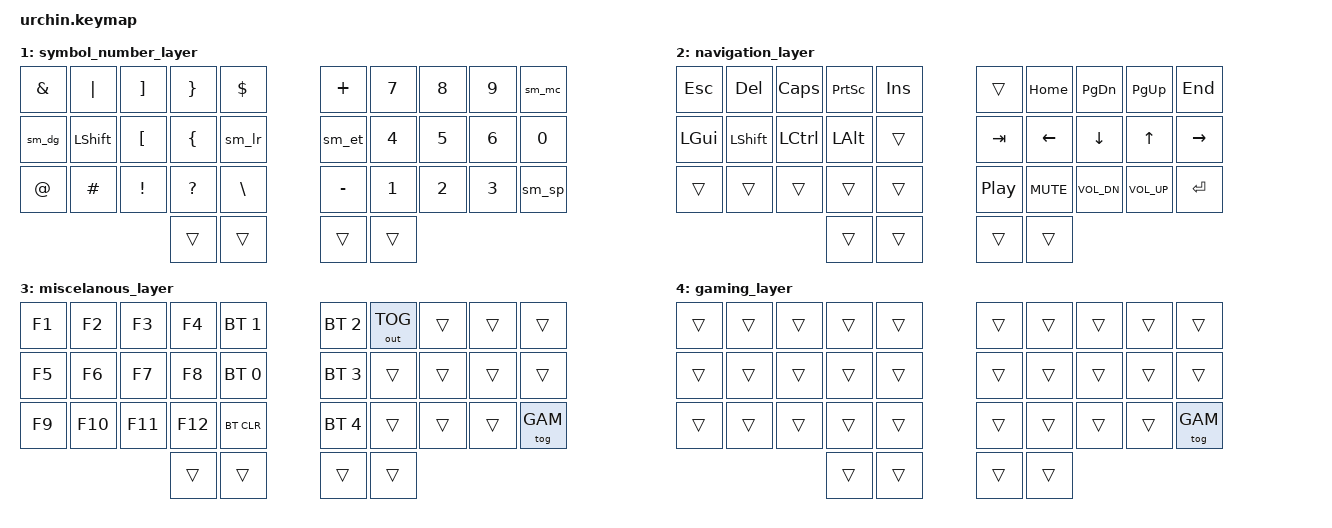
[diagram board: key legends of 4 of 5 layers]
// Copyright (c) 2022 The ZMK Contributors
// SPDX-License-Identifier: MIT

#include <behaviors.dtsi>
#include <dt-bindings/zmk/keys.h>
#include <dt-bindings/zmk/bt.h>
#include <dt-bindings/zmk/outputs.h>

// Home row mods macro
#define HRML(k1,k2,k3,k4) &ht LGUI k1 &ht LSHFT k2 &ht LCTRL k3  &ht LALT  k4
#define HRMR(k1,k2,k3) &ht RALT k1 &ht RCTRL k2 &ht RSHFT k3

#define WIN 0
#define SYM 1
#define NAV 2
#define MSC 3
#define GAM 4

/ {
    behaviors {
        ht: hold_tap {
            compatible = "zmk,behavior-hold-tap";
            #binding-cells = <2>;
            flavor = "tap-preferred";
            tapping-term-ms = <220>;
            quick-tap-ms = <150>;
            bindings = <&kp>, <&kp>;
        };
        sm_pu: left_parenthesis_underscore {
            compatible = "zmk,behavior-mod-morph";
            #binding-cells = <0>;
            bindings = <&kp LPAR>, <&kp UNDER>;
            mods = <(MOD_LSFT|MOD_RSFT)>;
        };
        sm_ca: comma_apostrophe {
            compatible = "zmk,behavior-mod-morph";
            #binding-cells = <0>;
            bindings = <&kp COMMA>, <&kp APOS>;
            mods = <(MOD_LSFT|MOD_RSFT)>;
        };
        sm_dq: dot_doublequote {
            compatible = "zmk,behavior-mod-morph";
            #binding-cells = <0>;
            bindings = <&kp DOT>, <&kp DQT>;
            mods = <(MOD_LSFT|MOD_RSFT)>;
        };
        sm_rs: return_slash {
            compatible = "zmk,behavior-mod-morph";
            #binding-cells = <0>;
            bindings = <&kp RET>, <&kp KP_SLASH>;
            mods = <(MOD_LSFT|MOD_RSFT)>;
        };

        sm_mc: multiply_exponent {
            compatible = "zmk,behavior-mod-morph";
            #binding-cells = <0>;
            bindings = <&kp KP_MULTIPLY>, <&kp CARET>;
            mods = <(MOD_LSFT|MOD_RSFT)>;
        };
        sm_dg: double_quote_grave {
            compatible = "zmk,behavior-mod-morph";
            #binding-cells = <0>;
            bindings = <&kp DQT>, <&kp GRAVE>;
            mods = <(MOD_LSFT|MOD_RSFT)>;
        };
        sm_lr: left_right_arrow {
            compatible = "zmk,behavior-mod-morph";
            #binding-cells = <0>;
            bindings = <&kp LT>, <&kp GT>;
            mods = <(MOD_LSFT|MOD_RSFT)>;
        };
        sm_et: equal_tilde {
            compatible = "zmk,behavior-mod-morph";
            #binding-cells = <0>;
            bindings = <&kp EQUAL>, <&kp TILDE>;
            mods = <(MOD_LSFT|MOD_RSFT)>;
        };
        sm_sp: slash_percent {
            compatible = "zmk,behavior-mod-morph";
            #binding-cells = <0>;
            bindings = <&kp KP_SLASH>, <&kp PRCNT>;
            mods = <(MOD_LSFT|MOD_RSFT)>;
        };
    };

    conditional_layers {
        compatible = "zmk,conditional-layers";
        tri_layer {
            if-layers = <SYM NAV>;
            then-layer = <MSC>;
        };
    };

    keymap {
        compatible = "zmk,keymap";

        default_layer {
            bindings = <
            // Main:                            &ht RCTRL k4
            // ╭───────────┬───────────┬───────────┬───────────┬───────────╮   ╭───────────┬───────────┬───────────┬───────────┬───────────╮
            // │     Q     │     W     │     E     │     R     │     T     │   │     Y     │     U     │     I     │     O     │     P     │
              &kp    Q    &kp    W    &kp    E    &kp    R    &kp    T        &kp    Y    &kp    U    &kp    I    &kp    O    &kp    P
            // ├───────────┼───────────┼───────────┼───────────┼───────────┤   ├───────────┼───────────┼───────────┼───────────┼───────────┤
            // │     A     │     S     │     D     │     F     │     G     │   │     H     │     J     │     K     │     L     │    ( _    │
            HRML(    A     ,     S     ,     D     ,     F )  &kp    G        &kp    H   HRMR(   J     ,     K     ,     L     )   &sm_pu
            // ├───────────┼───────────┼───────────┼───────────┼───────────┤   ├───────────┼───────────┼───────────┼───────────┼───────────┤
            // │     Z     │     X     │     C     │     V     │     B     │   │     N     │     M     │     ,'    │    . "    │    ; :    │
              &kp    Z    &kp    X    &kp    C    &kp    V    &kp    B        &kp    N    &kp    M         &sm_ca      &sm_dq &kp  SEMI
            // ╰───────────┴───────────┴───────────┼───────────┼───────────┤   ├───────────┼───────────┼───────────┴───────────┴───────────╯
            //                                     │    <XX    │   NAV ->  │   │  SYM  </  │    ._.    │
                                                  &kp   BSPC  &lt NAV TAB     &lt SYM RET &kp  SPACE  
            //                                     ╰───────────┴───────────╯   ╰───────────┴───────────╯
            >;
        };

        symbol_number_layer {
            bindings = <
            // Symbols and Numbers:
            // ╭───────────┬───────────┬───────────┬───────────┬───────────╮   ╭───────────┬───────────┬───────────┬───────────┬───────────╮
            // │     &     │     |     │     ]     │     }     │     $     │   │     +     │    7 &    │    8 *    │    9 (    │    * ^    │
              &kp  AMPS   &kp  PIPE   &kp  RBKT   &kp   RBRC  &kp  DOLLAR     &kp  PLUS   &kp    N7   &kp    N8   &kp    N9        &sm_mc
            // ├───────────┼───────────┼───────────┼───────────┼───────────┤   ├───────────┼───────────┼───────────┼───────────┼───────────┤
            // │    " `    │    /^\    │     [     │     {     │    < >    │   │    = ~    │    4 $    │    5 %    │    6 ^    │    0 )    │
                  &sm_dg  &kp  LSHFT  &kp  LBKT   &kp   LBRC       &sm_lr          &sm_et &kp    N4   &kp    N5   &kp    N6   &kp   N0
            // ├───────────┼───────────┼───────────┼───────────┼───────────┤   ├───────────┼───────────┼───────────┼───────────┼───────────┤
            // │     @     │     #     │     !     │     ?     │    \ |    │   │    - _    │    1 !    │    2 @    │    3 #    │    / %    │
              &kp    AT   &kp   HASH  &kp   EXCL  &kp  QMARK  &kp   BSLH      &kp  MINUS  &kp    N1   &kp    N2   &kp    N3       &sm_sp
            // ╰───────────┴───────────┴───────────┼───────────┼───────────┤   ├───────────┼───────────┼───────────┴───────────┴───────────╯
            //                                     │    <XX    │   MISC    │   │     V     │    ._.    │
                                                       &trans      &trans          &trans      &trans
            //                                     ╰───────────┴───────────╯   ╰───────────┴───────────╯
            >;
        };

        navigation_layer {
            bindings = <
            // Navigation:  
            // ╭───────────┬───────────┬───────────┬───────────┬───────────╮   ╭───────────┬───────────┬───────────┬───────────┬───────────╮
            // │    ESC    │    XX>    │ Caps Lock │ Print Scr │  Insert   │   │           │   HOME    │  PG DOWN  │   PG UP   │   END     │
              &kp   ESC   &kp   DEL   &kp   CAPS  &kp  PSCRN  &kp INSERT          &trans  &kp  HOME   &kp  PG_DN  &kp  PG_UP  &kp  END
            // ├───────────┼───────────┼───────────┼───────────┼───────────┤   ├───────────┼───────────┼───────────┼───────────┼───────────┤
            // │    GUI    │   SHIFT   │    CTRL   │    ALT    │           │   │     TAB   │     <     │     V     │    /^\    │     >     │
              &kp  LGUI  &kp  LSHIFT &kp   LCTRL  &kp   LALT      &trans      &kp    TAB  &kp   LEFT  &kp   DOWN  &kp    UP   &kp   RIGHT
            // ├───────────┼───────────┼───────────┼───────────┼───────────┤   ├───────────┼───────────┼───────────┼───────────┼───────────┤
            // │           │           │           │           │           │   │ PLY PAUSE │   MUTE    │ VOL DOWN  │  VOL UP   │    </     │
                  &trans      &trans      &trans      &trans      &trans      &kp  C_PP   &kp C_MUTE  &kp C_VOL_DN &kp C_VOL_UP &kp RET
            // ╰───────────┴───────────┴───────────┼───────────┼───────────┤   ├───────────┼───────────┼───────────┴───────────┴───────────╯
            //                                     │    <XX    │     V     │   │    MISC   │    ._.    │
                                                      &trans      &trans           &trans     &trans
            //                                     ╰───────────┴───────────╯   ╰───────────┴───────────╯
            >;
        };

        miscelanous_layer {
            bindings = <
            // Miscelanous:
            // ╭───────────┬───────────┬───────────┬───────────┬───────────╮   ╭───────────┬───────────┬───────────┬───────────┬───────────╮
            // │    Fn 1   │    Fn 2   │    Fn 3   │    Fn 4   │ PROFILE 1 │   │ PROFILE 2 │ TOGGLEOUT │           │           │           │
              &kp   F1    &kp   F2    &kp   F3    &kp    F4   &bt BT_SEL 1    &bt BT_SEL 2 &out OUT_TOG   &trans      &trans      &trans
            // ├───────────┼───────────┼───────────┼───────────┼───────────┤   ├───────────┼───────────┼───────────┼───────────┼───────────┤
            // │    Fn 5   │    Fn 6   │    Fn 7   │    Fn 8   │ PROFILE 0 │   │ PROFILE 3 │           │           │           │           │
              &kp   F5    &kp   F6    &kp   F7    &kp    F8   &bt BT_SEL 0    &bt BT_SEL 3    &trans      &trans      &trans      &trans
            // ├───────────┼───────────┼───────────┼───────────┼───────────┤   ├───────────┼───────────┼───────────┼───────────┼───────────┤
            // │    Fn 9   │    Fn 10  │    Fn 11  │    Fn 12  │  CLEAR BT │   │ PROFILE 4 │           │           │           │  Gaming   │
              &kp   F9    &kp   F10   &kp   F11   &kp    F12  &bt BT_CLR      &bt BT_SEL 4    &trans      &trans      &trans     &tog  GAM
            // ╰───────────┴───────────┴───────────┼───────────┼───────────┤   ├───────────┼───────────┼───────────┴───────────┴───────────╯
            //                                     │    <XX    │     V     │   │     V     │    ._.    │
                                                      &trans      &trans           &trans     &trans
            //                                     ╰───────────┴───────────╯   ╰───────────┴───────────╯
            >;
        };

        gaming_layer {
            bindings = <
            // Todo later? Gaming (should be standard with the shift gaps ctrl on the left most column):
            // ╭───────────┬───────────┬───────────┬───────────┬───────────╮   ╭───────────┬───────────┬───────────┬───────────┬───────────╮
            // │    TAB    │     Q     │     W     │     E     │     R     │   │           │           │           │           │           │
                  &trans      &trans      &trans      &trans      &trans          &trans      &trans      &trans      &trans      &trans
            // ├───────────┼───────────┼───────────┼───────────┼───────────┤   ├───────────┼───────────┼───────────┼───────────┼───────────┤
            // │   LSHIFT  |     A     │     S     │     D     │     F     │   │           │           │           │           │           │
                  &trans      &trans      &trans      &trans      &trans          &trans      &trans      &trans      &trans      &trans
            // ├───────────┼───────────┼───────────┼───────────┼───────────┤   ├───────────┼───────────┼───────────┼───────────┼───────────┤
            // │   LCTRL   │     Z     │     X     │     C     │     V     │   │           │           │           │           │           │
                  &trans      &trans      &trans      &trans      &trans          &trans      &trans      &trans      &trans  &tog  GAM
            // ╰───────────┴───────────┴───────────┼───────────┼───────────┤   ├───────────┼───────────┼───────────┴───────────┴───────────╯
            //                                     │           │   LALT    │   │           │           │
                                                      &trans      &trans          &trans      &trans
            //                                     ╰───────────┴───────────╯   ╰───────────┴───────────╯
            >;
        };
    };
};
